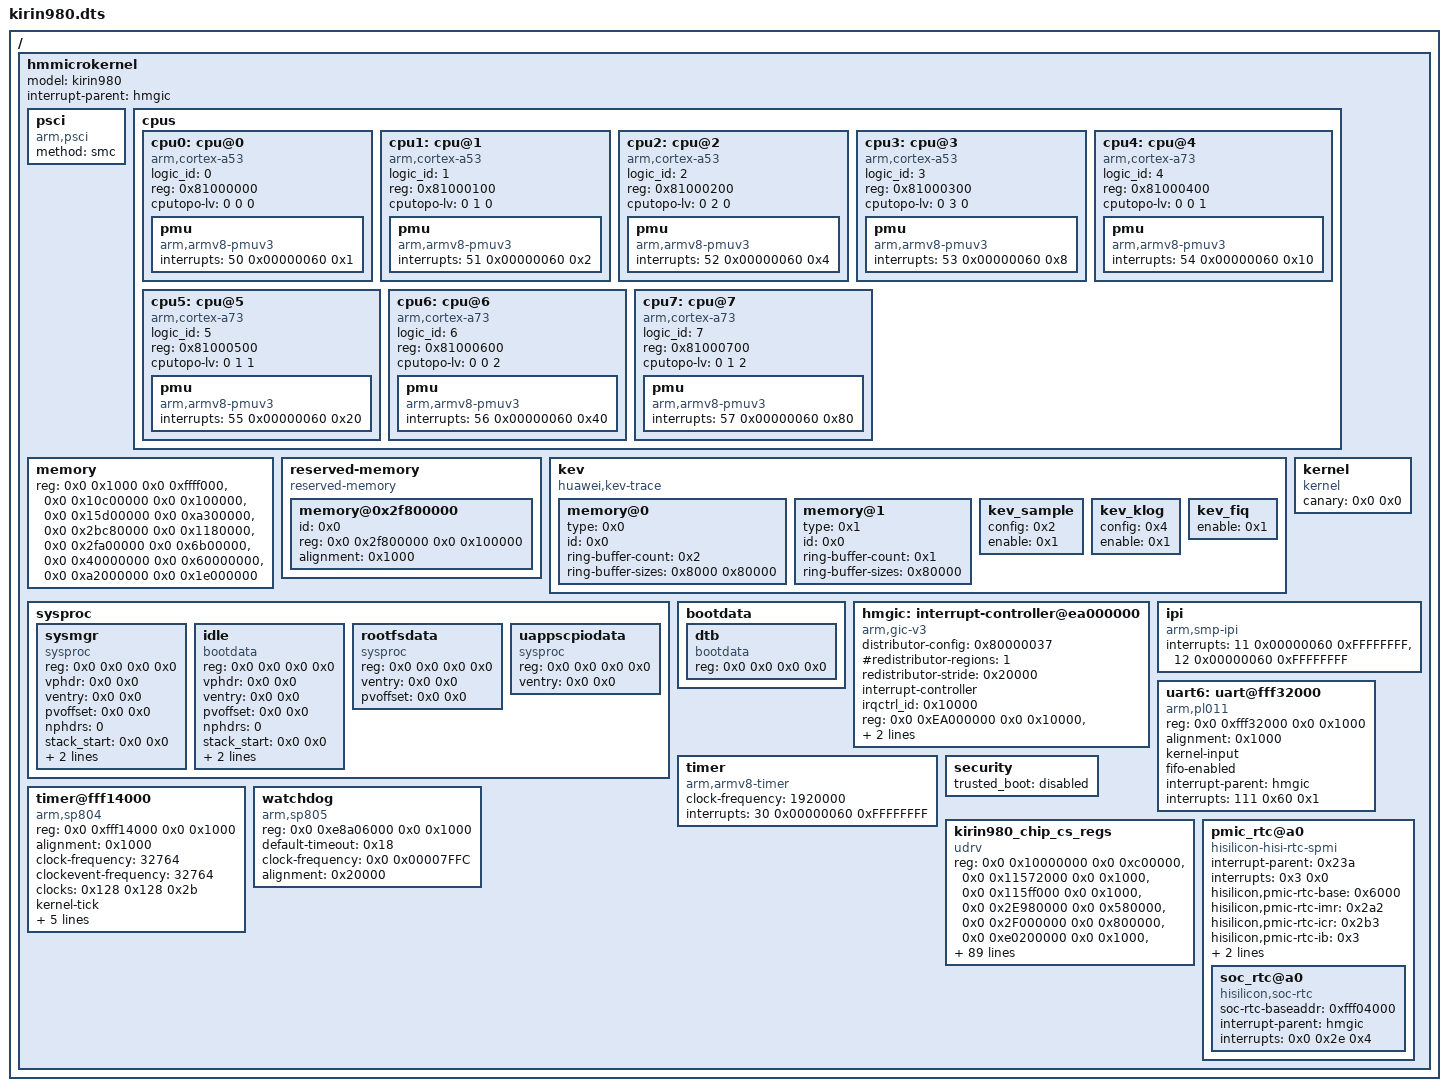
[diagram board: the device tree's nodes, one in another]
/dts-v1/;

/ {
	hmmicrokernel: hmmicrokernel { };
};

&hmmicrokernel {
	#address-cells = <2>;
	#size-cells = <2>;
	model = "kirin980";
	/* interrupt settings */
	interrupt-parent = <&hmgic>;

	psci {
		compatible = "arm,psci";
		method = "smc";
	};

	cpus {
		#address-cells = <1>;
		#size-cells = <0>;
		cpu0: cpu@0 {
			compatible = "arm,cortex-a53", "arm,armv8";
			device_type = "cpu";
			logic_id = <0>;
			reg = <0x81000000>;
			cputopo-lv = <0 0 0>;
			pmu {
				compatible = "arm,armv8-pmuv3";
				interrupts = <50 0x00000060 0x1>;
			};
		};
		cpu1: cpu@1 {
			compatible = "arm,cortex-a53", "arm,armv8";
			device_type = "cpu";
			logic_id = <1>;
			reg = <0x81000100>;
			cputopo-lv = <0 1 0>;
			pmu {
				compatible = "arm,armv8-pmuv3";
				interrupts = <51 0x00000060 0x2>;
			};
		};
		cpu2: cpu@2 {
			compatible = "arm,cortex-a53", "arm,armv8";
			device_type = "cpu";
			logic_id = <2>;
			reg = <0x81000200>;
			cputopo-lv = <0 2 0>;
			pmu {
				compatible = "arm,armv8-pmuv3";
				interrupts = <52 0x00000060 0x4>;
			};
		};
		cpu3: cpu@3 {
			compatible = "arm,cortex-a53", "arm,armv8";
			device_type = "cpu";
			logic_id = <3>;
			reg = <0x81000300>;
			cputopo-lv = <0 3 0>;
			pmu {
				compatible = "arm,armv8-pmuv3";
				interrupts = <53 0x00000060 0x8>;
			};
		};
		cpu4: cpu@4 {
			compatible = "arm,cortex-a73", "arm,armv8";
			device_type = "cpu";
			logic_id = <4>;
			reg = <0x81000400>;
			cputopo-lv = <0 0 1>;
			pmu {
				compatible = "arm,armv8-pmuv3";
				interrupts = <54 0x00000060 0x10>;
			};
		};
		cpu5: cpu@5 {
			compatible = "arm,cortex-a73", "arm,armv8";
			device_type = "cpu";
			logic_id = <5>;
			reg = <0x81000500>;
			cputopo-lv = <0 1 1>;
			pmu {
				compatible = "arm,armv8-pmuv3";
				interrupts = <55 0x00000060 0x20>;
			};
		};
		cpu6: cpu@6 {
			compatible = "arm,cortex-a73", "arm,armv8";
			device_type = "cpu";
			logic_id = <6>;
			reg = <0x81000600>;
			cputopo-lv = <0 0 2>;
			pmu {
				compatible = "arm,armv8-pmuv3";
				interrupts = <56 0x00000060 0x40>;
			};
		};
		cpu7: cpu@7 {
			compatible = "arm,cortex-a73", "arm,armv8";
			device_type = "cpu";
			logic_id = <7>;
			reg = <0x81000700>;
			cputopo-lv = <0 1 2>;
			pmu {
				compatible = "arm,armv8-pmuv3";
				interrupts = <57 0x00000060 0x80>;
			};
		};
	};

	memory {
		device_type = "memory";
		reg = <0x0 0x1000 0x0 0xffff000>,
		      <0x0 0x10c00000 0x0 0x100000>,
		      <0x0 0x15d00000 0x0 0xa300000>,
		      <0x0 0x2bc80000 0x0 0x1180000>,
		      <0x0 0x2fa00000 0x0 0x6b00000>,
		      <0x0 0x40000000 0x0 0x60000000>,
		      <0x0 0xa2000000 0x0 0x1e000000>;
	};

	reserved-memory {
		compatible = "reserved-memory";
		#address-cells = <2>;
		#size-cells = <2>;
		memory@0x2f800000 {
			id = <0x0>;
			reg = <0x0 0x2f800000 0x0 0x100000>;
			alignment = <0x1000>;
		};
	};

	kev {
		compatible = "huawei,kev-trace";

		memory@0 {
			type = <0x0>; /* normal memory */
			id = <0x0>;
			ring-buffer-count = <0x2>;
			/*
			 * Only ring buffer DATA sizes. Memory head and ring
			 * buffer heads are not included.
			 * ring buffer 0: 32K
			 * ring buffer 1: 512KB(perf)
			 */
			ring-buffer-sizes = <0x8000 0x80000> ;
		};
		memory@1 {
			type = <0x1>; /* reserved memory */
			id = <0x0>;
			ring-buffer-count = <0x1>;
			/*
			 * Only ring buffer DATA sizes. Memory head and ring
			 * buffer heads are not included.
			 * The size must be a power of 2 and some memory must
			 * be reserved for memory head and ring buffer heads.
			 * Therefore, the maximum size must be 512K, not 1M.
			 * ring buffer 2: 512K (klog)
			 */
			ring-buffer-sizes = <0x80000>;
		};
		kev_sample {
			config = <0x2>;
			enable = <0x1>;
		};
		kev_klog {
			config = <0x4>;
			enable = <0x1>;
		};
		kev_fiq {
			enable = <0x1>;
		};
	};

	sysproc {
		#address-cells = <2>;
		#size-cells = <2>;
		sysmgr {
			compatible = "sysproc", "sysmgr";
			/* filled by bootloader */
			reg      = <0x0 0x0 0x0 0x0>;
			vphdr    = <0x0 0x0>;
			ventry   = <0x0 0x0>;
			pvoffset = <0x0 0x0>;
			nphdrs   = <0>;
			stack_start = <0x0 0x0>;
			stack_end = <0x0 0x0>;
			canary = <0x0 0x0>;
		};
		idle {
			compatible = "bootdata", "idle";
			/* filled by bootloader */
			reg      = <0x0 0x0 0x0 0x0>;
			vphdr    = <0x0 0x0>;
			ventry   = <0x0 0x0>;
			pvoffset = <0x0 0x0>;
			nphdrs   = <0>;
			stack_start = <0x0 0x0>;
			stack_end = <0x0 0x0>;
			canary = <0x0 0x0>;
		};
		rootfsdata {
			compatible = "sysproc", "rootfs";
			/* filled by bootloader */
			reg      = <0x0 0x0 0x0 0x0>;
			ventry   = <0x0 0x0>;
			pvoffset = <0x0 0x0>;
		};

		uappscpiodata {
			compatible = "sysproc", "uappscpio";
			/* filled by bootloader */
			reg      = <0x0 0x0 0x0 0x0>;
			ventry   = <0x0 0x0>;
		};
	};

	kernel {
		compatible = "kernel";
		/* filled by bootloader */
		canary = <0x0 0x0>;
	};

	bootdata {
		#address-cells = <2>;
		#size-cells = <2>;
		dtb {
			compatible = "bootdata", "dtb";
			/* filled by bootloader */
			reg = <0x0 0x0 0x0 0x0>;
		};
	};

	/* See Documentation/dts-gic.md for interrupts and distributor_config */
	hmgic: interrupt-controller@ea000000 {
		compatible = "arm,gic-v3";

		#address-cells = <2>;
		#size-cells = <2>;
		distributor-config = <0x80000037>;
		#interrupt-cells = <3>;
		#redistributor-regions = <1>;
		redistributor-stride = <0x20000>;
		interrupt-controller;
		/* the value must be positive and the same as
		 * irqctrl_id in overlay.dts
		 */
		irqctrl_id = <0x10000>;

		reg =	<0x0 0xEA000000 0x0 0x10000>,   /* GICD */
			<0x0 0xEA040000 0x0 0x100000>;  /* GICR */
		alignment = <0x10000 0x10000>;
	};

	ipi {
		/* smp ipi */
		compatible = "arm,smp-ipi";

		/* interrupt settings:
		 * 1st cell: real hardware irq number
		 *     ARM recommendation: ID 0-7 for Non-Secure;
		 *                         ID 8-15 for Secure Interrupt
		 * 2nd cell: interrupt config
		 *     bit [27:26]: Group setting
		 *     bit [24]: Trigger Type
		 *     bit [23:8]: Reserved
		 *     bit [7:0]: Priority
		 * 3rd cell: interrupt target config
		 *     Warning: Send all cpus by defult
		 */
		interrupts =	<11 0x00000060 0xFFFFFFFF>, /* IPI_RESCHEDULE */
				<12 0x00000060 0xFFFFFFFF>; /* IPI_CALL_FUNC */
	};

	uart6: uart@fff32000 {
		compatible = "arm,pl011", "arm,pl011,uart";
		reg = <0x0 0xfff32000 0x0 0x1000>;
		alignment = <0x1000>;

		kernel-input;
		fifo-enabled;
		interrupt-parent = <&hmgic>;
		/* secure irq, group setting is 0b11 bit[27:26] */
		interrupts = <111 0x60 0x1>; /* pl011 uart6 interrupt for receiving */
	};

	timer {
		compatible = "arm,armv8-timer";
		clock-frequency = <1920000>;

		/* PPI 30: Non-secure physical timer
		 * level triggered, hwprio:0x60 */
		interrupts = <30 0x00000060 0xFFFFFFFF>;
	};

	timer@fff14000 {
		compatible = "arm,sp804", "arm,primecell";
		reg = <0x0 0xfff14000 0x0 0x1000>;
		alignment = <0x1000>;
		clock-frequency = <32764>;
		clockevent-frequency = <32764>;
		clocks = <0x128 0x128 0x2b>;
		clock-names = "osc32khz", "osc32khz", "apb_pclk";
		/* this timer should be driven by kernel */
		kernel-tick;
		status = "ok";
		prescale = <1>;
		value = <0xffffffff>;
		interrupt-parent = <&hmgic>;
		interrupts = <80 0x00000060 0xFFFFFFFF>,
			     <81 0x00000060 0xFFFFFFFF>;
	};

	watchdog {
		compatible = "arm,sp805", "arm,primecell";
		reg = <0x0 0xe8a06000 0x0 0x1000>;
		default-timeout = <0x18>;
		clock-frequency = <0x0 0x00007FFC>;
		status = "ok";
		alignment = <0x20000>;
	};

	security {
		trusted_boot = "disabled";
	};

	/* collect all used IOMEM here. */
	kirin980_chip_cs_regs {
		compatible = "udrv";
		#address-cells = <2>;
		#size-cells = <2>;
		reg = <0x0 0x10000000 0x0 0xc00000>,
		      <0x0 0x11572000 0x0 0x1000>, /* hisi,brightness_physmem */
		      <0x0 0x115ff000 0x0 0x1000>, /* mntn dump reserved memory */
		      <0x0 0x2E980000 0x0 0x580000>,
		      <0x0 0x2F000000 0x0 0x800000>, /* mntn black box */
		      <0x0 0xe0200000 0x0 0x1000>,
		      <0x0 0xe0440000 0x0 0x1000>,
		      <0x0 0xe0442000 0x0 0x1000>,
		      <0x0 0xe0453000 0x0 0x1000>,
		      <0x0 0xe804b000 0x0 0x1000>,
		      <0x0 0xe804e000 0x0 0xa000>,
		      <0x0 0xe82b9000 0x0 0x1000>,
		      <0x0 0xe82c0000 0x0 0x4000>, /* mali GPU */
		      <0x0 0xe8600000 0x0 0xc0000>,
		      <0x0 0xe8700000 0x0 0xc0000>,
		      <0x0 0xe87ff000 0x0 0x1000>,
		      <0x0 0xe8820000 0x0 0x1000>,
		      <0x0 0xe8900000 0x0 0x1000>,
		      <0x0 0xe8a02000 0x0 0x2000>,
		      <0x0 0xe8a06000 0x0 0x1000>,
		      <0x0 0xe8a09000 0x0 0x1000>,
		      <0x0 0xe896b000 0x0 0x1000>,
		      <0x0 0xe896c000 0x0 0x1000>,
		      <0x0 0xe8a0b000 0x0 0x1000>,
		      <0x0 0xe8a0c000 0x0 0x1000>,
		      <0x0 0xe8a0d000 0x0 0x1000>,
		      <0x0 0xe8a0e000 0x0 0x1000>,
		      <0x0 0xe8a0f000 0x0 0x1000>,
		      <0x0 0xe8a10000 0x0 0x1000>,
		      <0x0 0xe8a11000 0x0 0x1000>,
		      <0x0 0xe8a12000 0x0 0x1000>,
		      <0x0 0xe8a13000 0x0 0x1000>,
		      <0x0 0xe8a14000 0x0 0x1000>,
		      <0x0 0xe8a15000 0x0 0x1000>,
		      <0x0 0xe8a16000 0x0 0x1000>,
		      <0x0 0xe8a17000 0x0 0x1000>,
		      <0x0 0xe8a18000 0x0 0x1000>,
		      <0x0 0xe8a19000 0x0 0x1000>,
		      <0x0 0xe8a1a000 0x0 0x1000>,
		      <0x0 0xe8a1b000 0x0 0x1000>,
		      <0x0 0xe8a1c000 0x0 0x1000>,
		      <0x0 0xe8a1f000 0x0 0x1000>,
		      <0x0 0xe8a20000 0x0 0x1000>,
		      <0x0 0xec031000 0x0 0x1000>,
		      <0x0 0xec033000 0x0 0x1000>,
		      <0x0 0xec036000 0x0 0x1000>,
		      <0x0 0xec0c1000 0x0 0x2000>,
		      <0x0 0xf4000000 0x0 0x1000000>,
		      <0x0 0xf6000000 0x0 0x601000>,
		      <0x0 0xf6800000 0x0 0x4000>,
		      <0x0 0xfc000000 0x0 0x80000>,
		      <0x0 0xfc180000 0x0 0x1000>,
		      <0x0 0xfc182000 0x0 0x1000>,
		      <0x0 0xfc186000 0x0 0x1000>,
		      <0x0 0xfdf00000 0x0 0xc000>,
		      <0x0 0xfdf30000 0x0 0x1000>,
		      <0x0 0xff011000 0x0 0x1000>,
		      <0x0 0xff038000 0x0 0x18000>,
		      <0x0 0xff060000 0x0 0x1000>,
		      <0x0 0xff100000 0x0 0x100000>,
		      <0x0 0xff200000 0x0 0x1000>,
		      <0x0 0xffd75000 0x0 0x1000>,
		      <0x0 0xff340000 0x0 0x20000>,
		      <0x0 0xff37e000 0x0 0x1000>,
		      <0x0 0xff3c0000 0x0 0x20000>,
		      <0x0 0xff3e0000 0x0 0x1000>,
		      <0x0 0xffd7e000 0x0 0x1000>,
		      <0x0 0xfff00000 0x0 0x1000>,
		      <0x0 0xfff01000 0x0 0x1000>,
		      <0x0 0xfff02000 0x0 0x1000>,
		      <0x0 0xfff04000 0x0 0x1000>,
		      <0x0 0xfff08000 0x0 0x2000>,
		      <0x0 0xfff0a000 0x0 0x1000>,
		      <0x0 0xfff0b000 0x0 0x1000>,
		      <0x0 0xfff0c000 0x0 0x1000>,
		      <0x0 0xfff0d000 0x0 0x1000>,
		      <0x0 0xfff0e000 0x0 0x1000>,
		      <0x0 0xfff0f000 0x0 0x1000>,
		      <0x0 0xfff10000 0x0 0x1000>,
		      <0x0 0xfff11000 0x0 0x1000>,
		      <0x0 0xfff12000 0x0 0x1000>,
		      <0x0 0xfff14000 0x0 0x1000>,
		      <0x0 0xfff18000 0x0 0x4000>,
		      <0x0 0xfff1d000 0x0 0x1000>,
		      <0x0 0xfff21000 0x0 0x1000>,
		      <0x0 0xfff22000 0x0 0x1000>,
		      <0x0 0xfff24000 0x0 0x1000>,
		      <0x0 0xfff28000 0x0 0x1000>,
		      <0x0 0xfff29000 0x0 0x1000>,
		      <0x0 0xfff2a000 0x0 0x1000>,
		      <0x0 0xfff2b000 0x0 0x1000>,
		      <0x0 0xfff2e000 0x0 0x1000>,
		      <0x0 0xfff31000 0x0 0x1000>,
		      <0x0 0xfff32000 0x0 0x1000>,
		      <0x0 0xfff35000 0x0 0x1000>;
	};

	pmic_rtc@a0 {
		compatible = "hisilicon-hisi-rtc-spmi";
		interrupt-parent = <0x23a>;
		interrupts = <0x3 0x0>;
		interrupt-names = "hisi-pmic-rtc";
		hisilicon,pmic-rtc-base = <0x6000>;
		hisilicon,pmic-rtc-imr = <0x2a2>;
		hisilicon,pmic-rtc-icr = <0x2b3>;
		hisilicon,pmic-rtc-ib = <0x3>;
		hisilicon,pmic-rtc-xo-thrshd-pwroff-val = <0xffff>;
		status = "ok";

		soc_rtc@a0 {
			compatible = "hisilicon,soc-rtc";
			soc-rtc-baseaddr = <0xfff04000>;
			interrupt-parent = <&hmgic>;
			interrupts = <0x0 0x2e 0x4>;
		};
	};
};
